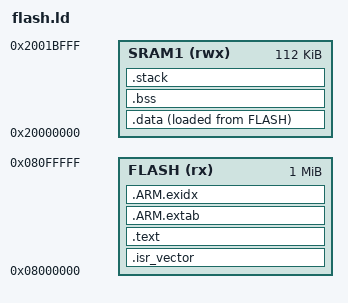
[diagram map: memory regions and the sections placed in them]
ENTRY(Reset_Handler)

MEMORY
{
    FLASH (rx) : ORIGIN = 0x08000000, LENGTH = 1024K
    SRAM1 (rwx) : ORIGIN = 0x20000000, LENGTH = 112K
}

SECTIONS
{
    .isr_vector : { KEEP(*(.isr_vector)) } > FLASH
    .text :
    {
        *(.text .text.*)
        *(.rodata .rodata.*)
        . = ALIGN(4);
    } > FLASH
    .ARM.extab : { *(.ARM.extab* .gnu.linkonce.armextab.*) } > FLASH
    .ARM.exidx : { *(.ARM.exidx* .gnu.linkonce.armexidx.*) } > FLASH

    .data :
    {
        . = ALIGN(4);
        _sdata = .;
        *(.data .data.*)
        . = ALIGN(4);
        _edata = .;
    } > SRAM1 AT > FLASH
    _sidata = LOADADDR(.data);

    .bss (NOLOAD) :
    {
        . = ALIGN(8);
        _sbss = .;
        *(.bss .bss.* COMMON)
        . = ALIGN(8);
        _ebss = .;
    } > SRAM1
    .stack (NOLOAD) :
    {
        . = ALIGN(8);
        . += 1024;
        _estack = .;
    } > SRAM1
}
